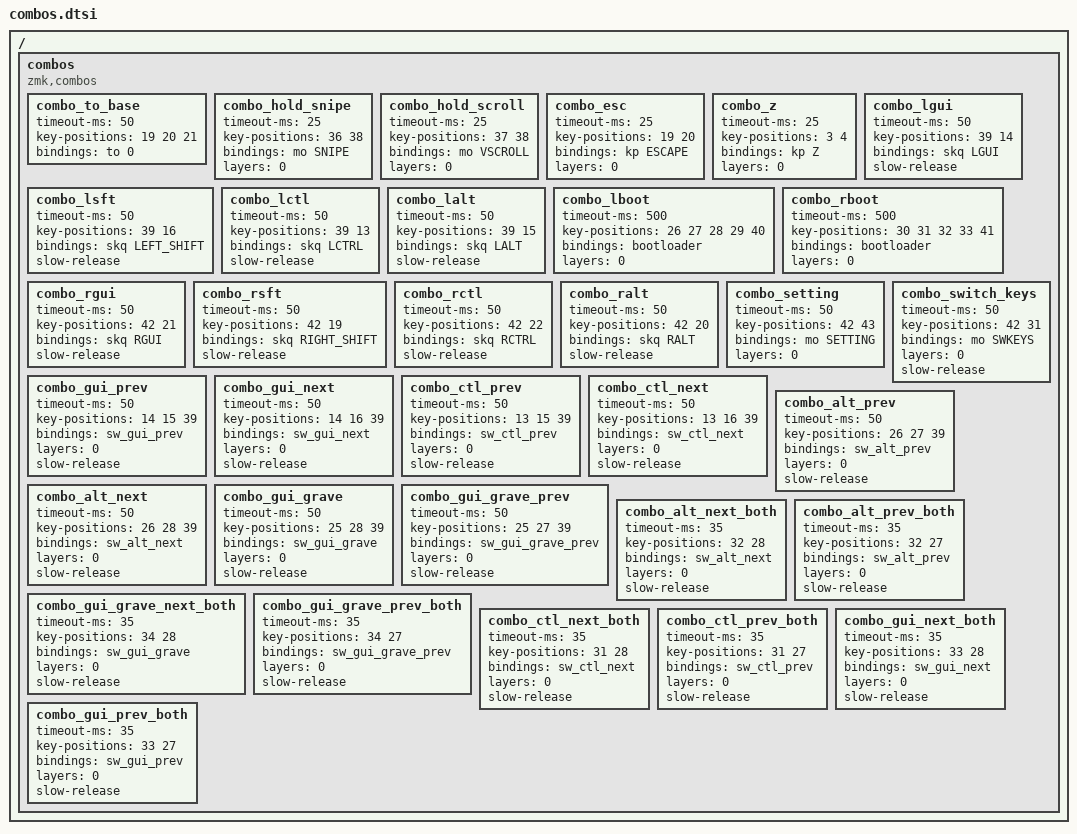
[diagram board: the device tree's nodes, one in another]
/ {
    combos {
        compatible = "zmk,combos";
        combo_to_base {
            timeout-ms = <50>;
            key-positions = <19 20 21>;
            bindings = <&to 0>;
        };

        combo_hold_snipe {
            timeout-ms = <25>;
            key-positions = <36 38>;
            bindings = <&mo SNIPE>;
            layers = <0>;
        };

        combo_hold_scroll {
            timeout-ms = <25>;
            key-positions = <37 38>;
            bindings = <&mo VSCROLL>;
            layers = <0>;
        };

        combo_esc {
            timeout-ms = <25>;
            key-positions = <19 20>;
            bindings = <&kp ESCAPE>;
            layers = <0>;
        };

        // LETTERS
        combo_z {
            timeout-ms = <25>;
            key-positions = <3 4>;
            bindings = <&kp Z>;
            layers = <0>;
        };

        // MODIFIERS
        combo_lgui {
            timeout-ms = <50>;
            key-positions = <39 14>;
            bindings = <&skq LGUI>;
            slow-release;
        };

        combo_lsft {
            timeout-ms = <50>;
            key-positions = <39 16>;
            bindings = <&skq LEFT_SHIFT>;
            slow-release;
        };

        combo_lctl {
            timeout-ms = <50>;
            key-positions = <39 13>;
            bindings = <&skq LCTRL>;
            slow-release;
        };

        combo_lalt {
            timeout-ms = <50>;
            key-positions = <39 15>;
            bindings = <&skq LALT>;
            slow-release;
        };

        combo_lboot {
            timeout-ms = <500>;
            key-positions = <26 27 28 29 40>;
            bindings = <&bootloader>;
            layers = <0>;
        };

        combo_rboot {
            timeout-ms = <500>;
            key-positions = <30 31 32 33 41>;
            bindings = <&bootloader>;
            layers = <0>;
        };

        combo_rgui {
            timeout-ms = <50>;
            key-positions = <42 21>;
            bindings = <&skq RGUI>;
            slow-release;
        };

        combo_rsft {
            timeout-ms = <50>;
            key-positions = <42 19>;
            bindings = <&skq RIGHT_SHIFT>;
            slow-release;
        };

        combo_rctl {
            timeout-ms = <50>;
            key-positions = <42 22>;
            bindings = <&skq RCTRL>;
            slow-release;
        };

        combo_ralt {
            timeout-ms = <50>;
            key-positions = <42 20>;
            bindings = <&skq RALT>;
            slow-release;
        };

        // LAYERS
        combo_setting {
            timeout-ms = <50>;
            key-positions = <42 43>;
            bindings = <&mo SETTING>;
            layers = <0>;
        };

        combo_switch_keys {
            timeout-ms = <50>;
            key-positions = <42 31>;
            bindings = <&mo SWKEYS>;
            layers = <0>;
            slow-release;
        };

        // SWITCHING
        combo_gui_prev {
            timeout-ms = <50>;
            key-positions = <14 15 39>;
            bindings = <&sw_gui_prev>;
            layers = <0>;
            slow-release;
        };

        combo_gui_next {
            timeout-ms = <50>;
            key-positions = <14 16 39>;
            bindings = <&sw_gui_next>;
            layers = <0>;
            slow-release;
        };

        combo_ctl_prev {
            timeout-ms = <50>;
            key-positions = <13 15 39>;
            bindings = <&sw_ctl_prev>;
            layers = <0>;
            slow-release;
        };

        combo_ctl_next {
            timeout-ms = <50>;
            key-positions = <13 16 39>;
            bindings = <&sw_ctl_next>;
            layers = <0>;
            slow-release;
        };

        combo_alt_prev {
            timeout-ms = <50>;
            key-positions = <26 27 39>;
            bindings = <&sw_alt_prev>;
            layers = <0>;
            slow-release;
        };

        combo_alt_next {
            timeout-ms = <50>;
            key-positions = <26 28 39>;
            bindings = <&sw_alt_next>;
            layers = <0>;
            slow-release;
        };

        combo_gui_grave {
            timeout-ms = <50>;
            key-positions = <25 28 39>;
            bindings = <&sw_gui_grave>;
            layers = <0>;
            slow-release;
        };

        combo_gui_grave_prev {
            timeout-ms = <50>;
            key-positions = <25 27 39>;
            bindings = <&sw_gui_grave_prev>;
            layers = <0>;
            slow-release;
        };

        combo_alt_next_both {
            timeout-ms = <35>;
            key-positions = <32 28>;
            bindings = <&sw_alt_next>;
            layers = <0>;
            slow-release;
        };

        combo_alt_prev_both {
            timeout-ms = <35>;
            key-positions = <32 27>;
            bindings = <&sw_alt_prev>;
            layers = <0>;
            slow-release;
        };

        combo_gui_grave_next_both {
            timeout-ms = <35>;
            key-positions = <34 28>;
            bindings = <&sw_gui_grave>;
            layers = <0>;
            slow-release;
        };

        combo_gui_grave_prev_both {
            timeout-ms = <35>;
            key-positions = <34 27>;
            bindings = <&sw_gui_grave_prev>;
            layers = <0>;
            slow-release;
        };
        
        combo_ctl_next_both {
            timeout-ms = <35>;
            key-positions = <31 28>;
            bindings = <&sw_ctl_next>;
            layers = <0>;
            slow-release;
        };
        
        combo_ctl_prev_both {
            timeout-ms = <35>;
            key-positions = <31 27>;
            bindings = <&sw_ctl_prev>;
            layers = <0>;
            slow-release;
        };


        combo_gui_next_both {
            timeout-ms = <35>;
            key-positions = <33 28>;
            bindings = <&sw_gui_next>;
            layers = <0>;
            slow-release;
        };


        combo_gui_prev_both {
            timeout-ms = <35>;
            key-positions = <33 27>;
            bindings = <&sw_gui_prev>;
            layers = <0>;
            slow-release;
        };
    };
};
